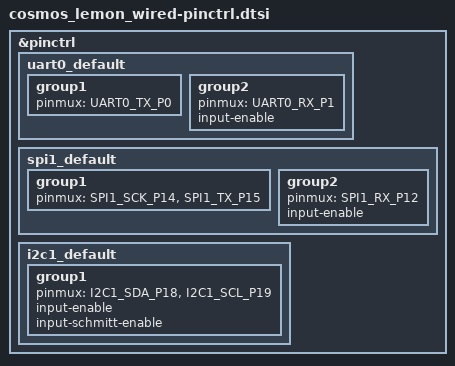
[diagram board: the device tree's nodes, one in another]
/*
 * Copyright (c) 2026 The ZMK Contributors
 *
 * SPDX-License-Identifier: MIT
 *
 * Pinctrl groups for the Cosmos Lemon Wired peripherals that the per-shield
 * board overlay enables. UART0 GP0/GP1 carries the wired-split link;
 * SPI1 (GP12/14/15 + GPIO CS) and I2C1 (GP18/19) feed the VIK connector.
 */

#include <zephyr/dt-bindings/pinctrl/rpi-pico-rp2040-pinctrl.h>

&pinctrl {
	uart0_default: uart0_default {
		group1 {
			pinmux = <UART0_TX_P0>;
		};
		group2 {
			pinmux = <UART0_RX_P1>;
			input-enable;
		};
	};

	spi1_default: spi1_default {
		group1 {
			pinmux = <SPI1_SCK_P14>, <SPI1_TX_P15>;
		};
		group2 {
			pinmux = <SPI1_RX_P12>;
			input-enable;
		};
	};

	i2c1_default: i2c1_default {
		group1 {
			pinmux = <I2C1_SDA_P18>, <I2C1_SCL_P19>;
			input-enable;
			input-schmitt-enable;
		};
	};
};
